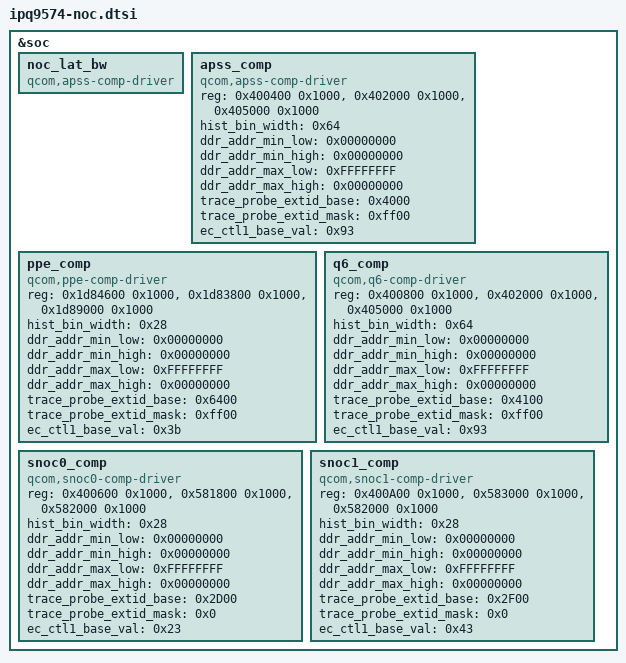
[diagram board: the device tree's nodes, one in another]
// SPDX-License-Identifier: BSD-3-Clause
/*
 * IPQ9574 NoC device tree source
 *
 * Copyright (c) 2025 Qualcomm Innovation Center, Inc. All rights reserved.
 */

&soc {
	noc_lat_bw {
		compatible = "qcom,apss-comp-driver";
		status = "okay";
	};

	apss_comp {
		compatible = "qcom,apss-comp-driver";
		reg = <0x400400 0x1000>,<0x402000 0x1000>, <0x405000 0x1000>;
		reg-names = "tenureprobe-base", "traceprobe-base", "eventcounter-base";
		hist_bin_width = <0x64>;
		ddr_addr_min_low = <0x00000000>;
		ddr_addr_min_high = <0x00000000>;
		ddr_addr_max_low = <0xFFFFFFFF>;
		ddr_addr_max_high = <0x00000000>;
		trace_probe_extid_base = <0x4000>;
		trace_probe_extid_mask = <0xff00>;
		ec_ctl1_base_val = <0x93>;
		status = "okay";
	};

	ppe_comp {
		compatible = "qcom,ppe-comp-driver";
		reg = <0x1d84600 0x1000>,<0x1d83800 0x1000>, <0x1d89000 0x1000>;
		reg-names = "tenureprobe-base", "traceprobe-base", "eventcounter-base";
		hist_bin_width = <0x28>;
		ddr_addr_min_low = <0x00000000>;
		ddr_addr_min_high = <0x00000000>;
		ddr_addr_max_low = <0xFFFFFFFF>;
		ddr_addr_max_high = <0x00000000>;
		trace_probe_extid_base = <0x6400>;
		trace_probe_extid_mask = <0xff00>;
		ec_ctl1_base_val = <0x3b>;
		status = "okay";
	};

	q6_comp {
		compatible = "qcom,q6-comp-driver";
		reg = <0x400800 0x1000>, <0x402000 0x1000>, <0x405000 0x1000>;
		reg-names = "tenureprobe-base", "traceprobe-base", "eventcounter-base" ;
		hist_bin_width = <0x64>;
		ddr_addr_min_low = <0x00000000>;
		ddr_addr_min_high = <0x00000000>;
		ddr_addr_max_low = <0xFFFFFFFF>;
		ddr_addr_max_high = <0x00000000>;
		trace_probe_extid_base = <0x4100>;
		trace_probe_extid_mask = <0xff00>;
		ec_ctl1_base_val = <0x93>;
		status = "okay";
	};

	snoc0_comp{
		compatible = "qcom,snoc0-comp-driver";
		reg = <0x400600 0x1000>, <0x581800 0x1000>, <0x582000 0x1000>;
		reg-names = "tenureprobe-base", "traceprobe-base", "eventcounter-base" ;
		hist_bin_width = <0x28>;
		ddr_addr_min_low = <0x00000000>;
		ddr_addr_min_high = <0x00000000>;
		ddr_addr_max_low = <0xFFFFFFFF>;
		ddr_addr_max_high = <0x00000000>;
		trace_probe_extid_base = <0x2D00>;
		trace_probe_extid_mask = <0x0>;
		ec_ctl1_base_val = <0x23>;
		status = "okay";
	};

	snoc1_comp{
		compatible = "qcom,snoc1-comp-driver";
		reg = <0x400A00 0x1000>, <0x583000 0x1000>, <0x582000 0x1000>;
		reg-names = "tenureprobe-base", "traceprobe-base", "eventcounter-base" ;
		hist_bin_width = <0x28>;
		ddr_addr_min_low = <0x00000000>;
		ddr_addr_min_high = <0x00000000>;
		ddr_addr_max_low = <0xFFFFFFFF>;
		ddr_addr_max_high = <0x00000000>;
		trace_probe_extid_base = <0x2F00>;
		trace_probe_extid_mask = <0x0>;
		ec_ctl1_base_val = <0x43>;
		status = "okay";
	};
};
